# STM32C5A3xx register map
File version: 1.0
Registers are 32-bit, read-write, reset 0x0 unless marked. A register's access mark holds for its fields unless they carry their own. Offsets are from the block's base; [hi:lo] are bit positions; {n}, {i} and the like mark numbered series.

## RCC — Reset and clock control (RCC)
Base 0x44020C00
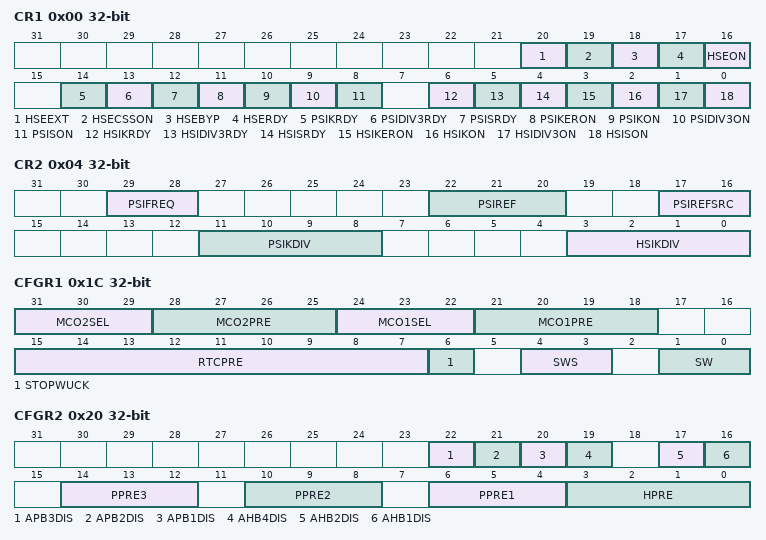
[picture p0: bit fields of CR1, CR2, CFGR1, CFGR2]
0x00 CR1 — RCC clock control register
  [20] HSEEXT
  [19] HSECSSON
  [18] HSEBYP — HSE clock bypass
  [17] HSERDY — HSE clock ready flag
  [16] HSEON — HSE clock enable
  [14] PSIKRDY — PSIK clock ready flag
  [13] PSIDIV3RDY — PSIDIV3 clock ready flag
  [12] PSISRDY — PSIS clock ready flag
  [11] PSIKERON — PSI clock enable in Stop mode
  [10] PSIKON — PSIK clock enable
  [9] PSIDIV3ON — PSIDIV3 clock enable
  [8] PSISON — PSIS clock enable
  [6] HSIKRDY — HSIK clock ready flag
  [5] HSIDIV3RDY — HSIDIV3 clock ready flag
  [4] HSISRDY — HSIS clock ready flag
  [3] HSIKERON — HSI clock enable in Stop mode
  [2] HSIKON — HSIK clock enable
  [1] HSIDIV3ON — HSIDIV3 clock enable
  [0] HSISON — HSIS clock enable
0x04 CR2 — RCC clock control register
  [29:28] PSIFREQ
  [22:20] PSIREF
  [17:16] PSIREFSRC
  [11:8] PSIKDIV — PSI clock out divider factor
  [3:0] HSIKDIV — HSI clock out divider factor
0x1C CFGR1 — RCC clock configuration register1
  [31:29] MCO2SEL — Microcontroller clock output 2
  [28:25] MCO2PRE — MCO2 prescaler
  [24:22] MCO1SEL — Microcontroller clock output 1
  [21:18] MCO1PRE — MCO1 prescaler
  [15:7] RTCPRE
  [6] STOPWUCK
  [4:3] SWS — System clock switch status
  [1:0] SW
0x20 CFGR2 — RCC CPU domain clock configuration register 2
  [22] APB3DIS
  [21] APB2DIS — APB2 clock disable value
  [20] APB1DIS — APB1 clock disable value
  [19] AHB4DIS — AHB4 clock disable value
  [17] AHB2DIS — AHB2 clock disable
  [16] AHB1DIS — AHB1 clock disable
  [14:12] PPRE3 — APB low-speed prescaler (APB3)
  [10:8] PPRE2 — APB high-speed prescaler (APB2)
  [6:4] PPRE1 — APB low-speed prescaler (APB1)
  [3:0] HPRE — AHB prescaler
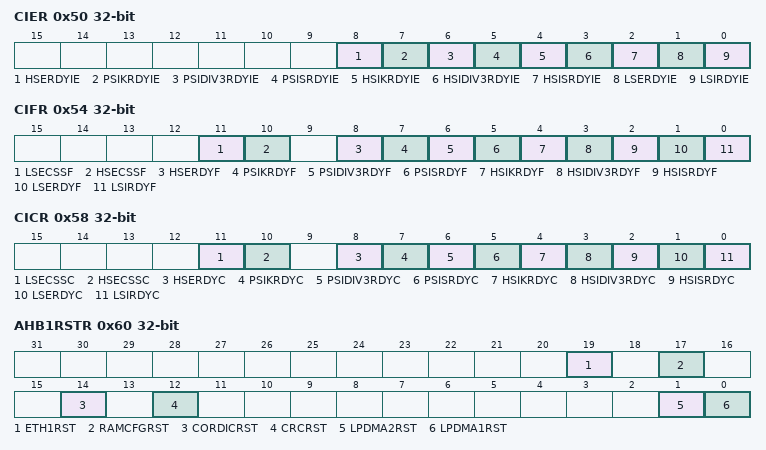
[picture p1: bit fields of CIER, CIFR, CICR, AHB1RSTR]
0x50 CIER — RCC clock source interrupt enable register
  [8] HSERDYIE — HSE ready interrupt enable
  [7] PSIKRDYIE — PSIK ready interrupt enable
  [6] PSIDIV3RDYIE — PSIDIV3 ready interrupt enable
  [5] PSISRDYIE — PSIS ready interrupt enable
  [4] HSIKRDYIE — HSIK ready interrupt enable
  [3] HSIDIV3RDYIE — HSIDIV3 ready interrupt enable
  [2] HSISRDYIE — HSIS ready interrupt enable
  [1] LSERDYIE — LSE ready interrupt enable
  [0] LSIRDYIE — LSI ready interrupt enable
0x54 CIFR ro — RCC clock source interrupt flag register
  [11] LSECSSF
  [10] HSECSSF
  [8] HSERDYF — HSE ready interrupt flag
  [7] PSIKRDYF — PSIK ready interrupt flag
  [6] PSIDIV3RDYF — PSIDIV3 ready interrupt flag
  [5] PSISRDYF — PSIS ready interrupt flag
  [4] HSIKRDYF — HSIK ready interrupt flag
  [3] HSIDIV3RDYF — HSIDIV3 ready interrupt flag
  [2] HSISRDYF — HSIS ready interrupt flag
  [1] LSERDYF — LSE ready interrupt flag
  [0] LSIRDYF — LSI ready interrupt flag
0x58 CICR — RCC clock source interrupt clear register
  [11] LSECSSC
  [10] HSECSSC
  [8] HSERDYC — HSE ready interrupt clear
  [7] PSIKRDYC — PSIK ready interrupt clear
  [6] PSIDIV3RDYC — PSIDIV3 ready interrupt clear
  [5] PSISRDYC — PSIS ready interrupt clear
  [4] HSIKRDYC — HSIK ready interrupt clear
  [3] HSIDIV3RDYC — HSIDIV3 ready interrupt clear
  [2] HSISRDYC — HSIS ready interrupt clear
  [1] LSERDYC — LSE ready interrupt clear
  [0] LSIRDYC — LSI ready interrupt clear
0x60 AHB1RSTR — RCC AHB1 reset register
  [19] ETH1RST — ETH1RST (EHT1 block reset)
  [17] RAMCFGRST — RAMCFG reset
  [14] CORDICRST — CORDIC reset
  [12] CRCRST — CRC reset
  [1] LPDMA2RST — LPDMA2 reset
  [0] LPDMA1RST — LPDMA1 reset
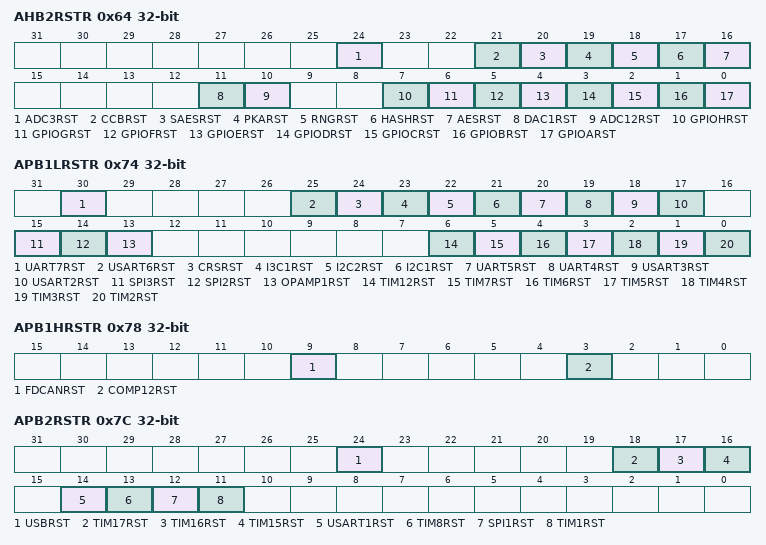
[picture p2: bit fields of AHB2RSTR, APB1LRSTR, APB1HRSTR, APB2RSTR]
0x64 AHB2RSTR — RCC AHB2 peripheral reset register
  [24] ADC3RST — ADC3 reset
  [21] CCBRST — CCBRST (CCB block reset)
  [20] SAESRST — SAESRST (SAES block reset)
  [19] PKARST — PKARST (PKA block reset)
  [18] RNGRST — RNG reset
  [17] HASHRST — HASH reset
  [16] AESRST — AES reset
  [11] DAC1RST — DAC reset
  [10] ADC12RST — ADC1 and ADC2 reset
  [7] GPIOHRST — GPIOH reset
  [6] GPIOGRST — GPIOG reset
  [5] GPIOFRST — GPIOF reset
  [4] GPIOERST — GPIOE reset
  [3] GPIODRST — GPIOD reset
  [2] GPIOCRST — GPIOC reset
  [1] GPIOBRST — GPIOB reset
  [0] GPIOARST — GPIOA reset
0x6C AHB4RSTR — RCC AHB4 peripheral reset register
  [20] XSPI1RST — XSPI1 reset
0x74 APB1LRSTR — RCC APB1 peripheral low reset register
  [30] UART7RST — UART7RST (UART7 block reset)
  [25] USART6RST — USART6RST (USART6 block reset)
  [24] CRSRST — CRS reset
  [23] I3C1RST — I3C1 block reset
  [22] I2C2RST — I2C2 reset
  [21] I2C1RST — I2C1 reset
  [20] UART5RST — UART5 reset
  [19] UART4RST — UART4 reset
  [18] USART3RST — USART3 reset
  [17] USART2RST — USART2 reset
  [15] SPI3RST — SPI3 reset
  [14] SPI2RST — SPI2 reset
  [13] OPAMP1RST — OPAMP1 reset
  [6] TIM12RST — TIM12 reset
  [5] TIM7RST — TIM7 reset
  [4] TIM6RST — TIM6 reset
  [3] TIM5RST — TIM5 reset
  [2] TIM4RST — TIM4RST (TIM4 block reset)
  [1] TIM3RST — TIM3 reset
  [0] TIM2RST — TIM2 reset
0x78 APB1HRSTR — RCC APB1 peripheral high reset register
  [9] FDCANRST — FDCAN1 reset
  [3] COMP12RST — COMP1 and COMP2 reset
0x7C APB2RSTR — RCC APB2 peripheral reset register
  [24] USBRST — USBRST (USB block reset)
  [18] TIM17RST — TIM17 reset
  [17] TIM16RST — TIM16 reset
  [16] TIM15RST — TIM15 reset
  [14] USART1RST — USART1 reset
  [13] TIM8RST — TIM8 reset
  [12] SPI1RST — SPI1 reset
  [11] TIM1RST — TIM1 reset
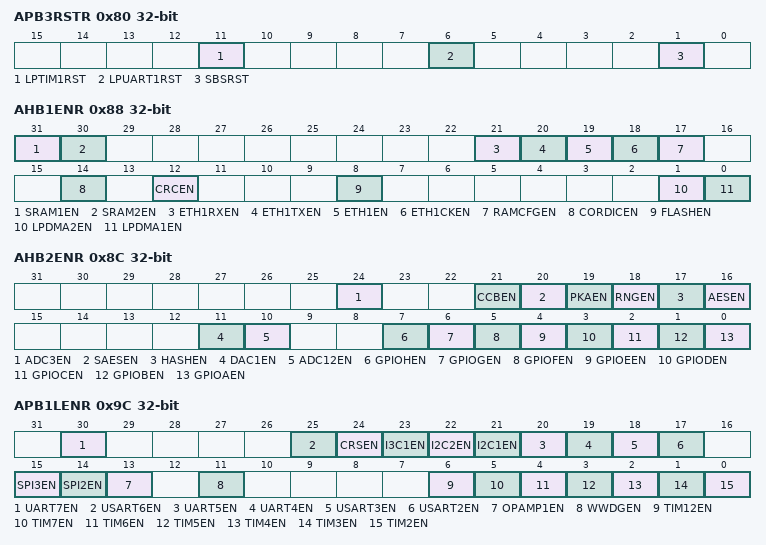
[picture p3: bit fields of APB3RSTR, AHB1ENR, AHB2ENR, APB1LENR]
0x80 APB3RSTR — RCC APB3 peripheral reset register
  [11] LPTIM1RST — LPTIM1RST (LPTIM1 block reset)
  [6] LPUART1RST — LPUART1 reset
  [1] SBSRST — SBS reset
0x88 AHB1ENR — RCC AHB1 peripheral clock register
  [31] SRAM1EN — SRAM1 clock enable
  [30] SRAM2EN — SRAM2 clock enable
  [21] ETH1RXEN — ETH1RXEN (ETH1RX clock enable)
  [20] ETH1TXEN — ETH1TXEN (ETH1TX clock enable)
  [19] ETH1EN — ETH1EN (ETH1 clock enable)
  [18] ETH1CKEN — ETH1CKEN (ETH1CK clock enable)
  [17] RAMCFGEN — RAMCFG clock enable
  [14] CORDICEN — CORDIC clock enable
  [12] CRCEN — CRC clock enable
  [8] FLASHEN — Flash interface clock enable
  [1] LPDMA2EN — LPDMA2 clock enable
  [0] LPDMA1EN — LPDMA1 clock enable
0x8C AHB2ENR — RCC AHB2 peripheral clock register
  [24] ADC3EN — ADC3 clock enable
  [21] CCBEN — CCBEN (CCB clock enable)
  [20] SAESEN — SAESEN (SAES clock enable)
  [19] PKAEN — PKAEN (PKA clock enable)
  [18] RNGEN — RNG clock enable
  [17] HASHEN — HASH clock enable
  [16] AESEN — AES clock enable
  [11] DAC1EN — DAC1 clock enable
  [10] ADC12EN — ADC1 and ADC2 clock enable
  [7] GPIOHEN — GPIOH clock enable
  [6] GPIOGEN — GPIOG clock enable
  [5] GPIOFEN — GPIOF clock enable
  [4] GPIOEEN — GPIOE clock enable
  [3] GPIODEN — GPIOD clock enable
  [2] GPIOCEN — GPIOC clock enable
  [1] GPIOBEN — GPIOB clock enable
  [0] GPIOAEN — GPIOA clock enable
0x94 AHB4ENR — RCC AHB4 peripheral clock register
  [20] XSPI1EN — XSPI1 clock enable
0x9C APB1LENR — RCC APB1 peripheral clock register
  [30] UART7EN — UART7EN (UART7 clock enable)
  [25] USART6EN — USART6EN (USART6 clock enable)
  [24] CRSEN — CRS clock enable
  [23] I3C1EN — I3C1 clock enable
  [22] I2C2EN — I2C2 clock enable
  [21] I2C1EN — I2C1 clock enable
  [20] UART5EN — UART5 clock enable
  [19] UART4EN — UART4 clock enable
  [18] USART3EN — USART3 clock enable
  [17] USART2EN — USART2 clock enable
  [15] SPI3EN — SPI3 clock enable
  [14] SPI2EN — SPI2 clock enable
  [13] OPAMP1EN — OPAMP1 clock enable
  [11] WWDGEN — WWDG clock enable
  [6] TIM12EN — TIM12 clock enable
  [5] TIM7EN — TIM7 clock enable
  [4] TIM6EN — TIM6 clock enable
  [3] TIM5EN — TIM5 clock enable
  [2] TIM4EN — TIM4EN (TIM4 clock enable)
  [1] TIM3EN — TIM3 clock enable
  [0] TIM2EN — TIM2 clock enable
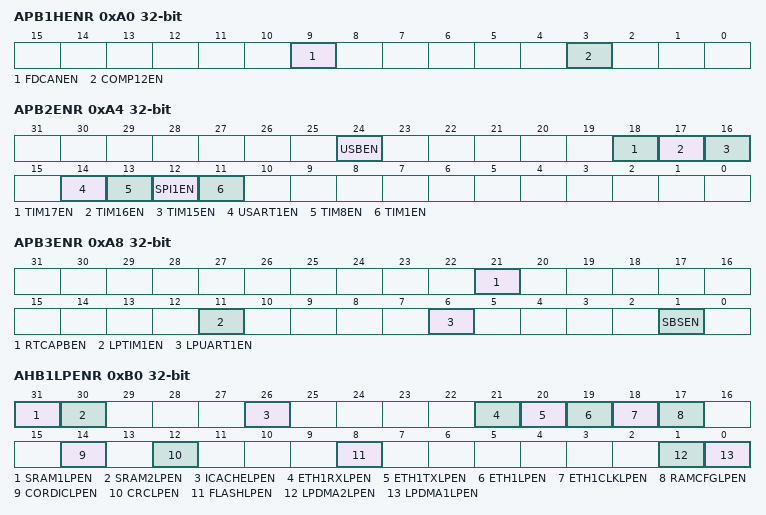
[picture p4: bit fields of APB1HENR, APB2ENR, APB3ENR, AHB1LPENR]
0xA0 APB1HENR — RCC APB1 peripheral clock register
  [9] FDCANEN — FDCAN1 clock enable
  [3] COMP12EN — COMP1 and COMP2 clock enable
0xA4 APB2ENR — RCC APB2 peripheral clock register
  [24] USBEN — USBEN (USB clock enable)
  [18] TIM17EN — TIM17 clock enable
  [17] TIM16EN — TIM16 clock enable
  [16] TIM15EN — TIM15 clock enable
  [14] USART1EN — USART1 clock enable
  [13] TIM8EN — TIM8 clock enable
  [12] SPI1EN — SPI1 clock enable
  [11] TIM1EN — TIM1 clock enable
0xA8 APB3ENR — RCC APB3 peripheral clock register
  [21] RTCAPBEN — RTC APB interface clock enable
  [11] LPTIM1EN — LPTIM1EN (LPTIM1 clock enable)
  [6] LPUART1EN — LPUART1 clock enable
  [1] SBSEN — SBS clock enable
0xB0 AHB1LPENR — RCC AHB1 sleep clock register
  [31] SRAM1LPEN, [30] SRAM2LPEN, [26] ICACHELPEN, [21] ETH1RXLPEN, [20] ETH1TXLPEN, [19] ETH1LPEN, [18] ETH1CLKLPEN, [17] RAMCFGLPEN, [14] CORDICLPEN, [12] CRCLPEN, [8] FLASHLPEN, [1] LPDMA2LPEN, [0] LPDMA1LPEN
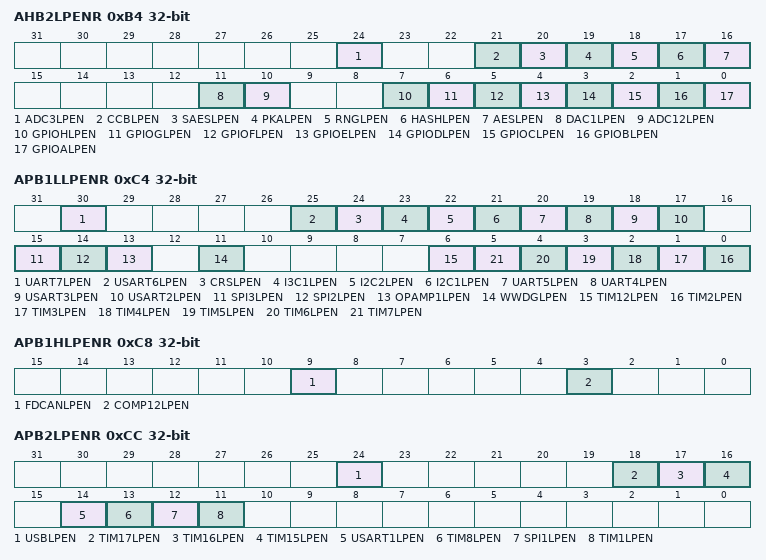
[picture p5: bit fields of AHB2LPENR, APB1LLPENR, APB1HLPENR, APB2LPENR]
0xB4 AHB2LPENR — RCC AHB2 sleep clock register
  [24] ADC3LPEN, [21] CCBLPEN, [20] SAESLPEN, [19] PKALPEN, [18] RNGLPEN, [17] HASHLPEN, [16] AESLPEN, [11] DAC1LPEN, [10] ADC12LPEN, [7] GPIOHLPEN, [6] GPIOGLPEN, [5] GPIOFLPEN, [4] GPIOELPEN, [3] GPIODLPEN, [2] GPIOCLPEN, [1] GPIOBLPEN, [0] GPIOALPEN
0xBC AHB4LPENR — RCC AHB4 peripheral sleep clock register
  [20] XSPI1LPEN
0xC4 APB1LLPENR — RCC APB1 sleep clock register
  [30] UART7LPEN, [25] USART6LPEN, [24] CRSLPEN, [23] I3C1LPEN, [22] I2C2LPEN, [21] I2C1LPEN, [20] UART5LPEN, [19] UART4LPEN, [18] USART3LPEN, [17] USART2LPEN, [15] SPI3LPEN, [14] SPI2LPEN, [13] OPAMP1LPEN, [11] WWDGLPEN, [6] TIM12LPEN, [n-2] TIM{n}LPEN (n=2..7)
0xC8 APB1HLPENR — RCC APB1 sleep clock register
  [9] FDCANLPEN, [3] COMP12LPEN
0xCC APB2LPENR — RCC APB2 sleep clock register
  [24] USBLPEN, [18] TIM17LPEN, [17] TIM16LPEN, [16] TIM15LPEN, [14] USART1LPEN, [13] TIM8LPEN, [12] SPI1LPEN, [11] TIM1LPEN
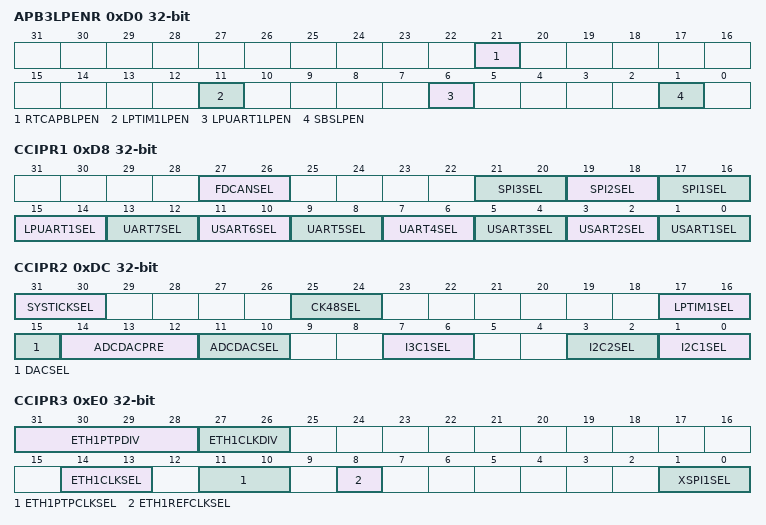
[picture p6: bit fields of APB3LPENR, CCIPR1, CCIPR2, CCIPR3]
0xD0 APB3LPENR — RCC APB3 sleep clock register
  [21] RTCAPBLPEN, [11] LPTIM1LPEN, [6] LPUART1LPEN, [1] SBSLPEN
0xD8 CCIPR1 — RCC kernel clock configuration register
  [27:26] FDCANSEL, [21:20] SPI3SEL, [19:18] SPI2SEL, [17:16] SPI1SEL, [15:14] LPUART1SEL, [13:12] UART7SEL, [11:10] USART6SEL, [9:8] UART5SEL, [7:6] UART4SEL, [5:4] USART3SEL, [3:2] USART2SEL, [1:0] USART1SEL
0xDC CCIPR2 — RCC kernel clock configuration register
  [31:30] SYSTICKSEL — SYSTICK clock source selection
  [25:24] CK48SEL — CK48 clock source selection
  [17:16] LPTIM1SEL
  [15] DACSEL — DAC sample and hold clock
  [14:12] ADCDACPRE
  [11:10] ADCDACSEL
  [7:6] I3C1SEL
  [3:2] I2C2SEL
  [1:0] I2C1SEL
0xE0 CCIPR3 — RCC kernel clock configuration register
  [31:28] ETH1PTPDIV — Ethernet PTP clock division
  [27:26] ETH1CLKDIV — Ethernet clock division
  [14:13] ETH1CLKSEL
  [11:10] ETH1PTPCLKSEL
  [8] ETH1REFCLKSEL
  [1:0] XSPI1SEL
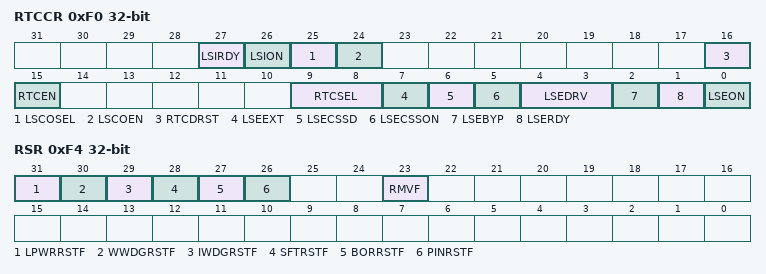
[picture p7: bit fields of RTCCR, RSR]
0xF0 RTCCR — RCC RTC domain control register
  [27] LSIRDY — LSI oscillator ready
  [26] LSION — LSI oscillator enable
  [25] LSCOSEL
  [24] LSCOEN
  [16] RTCDRST — RTC domain software reset
  [15] RTCEN — RTC clock enable
  [9:8] RTCSEL — RTC clock source selection
  [7] LSEEXT
  [6] LSECSSD
  [5] LSECSSON
  [4:3] LSEDRV
  [2] LSEBYP — LSE oscillator bypass
  [1] LSERDY — LSE oscillator ready
  [0] LSEON — LSE oscillator enabled
0xF4 RSR — RCC reset status register
  [31] LPWRRSTF — Low-power reset flag
  [30] WWDGRSTF — Window watchdog reset flag
  [29] IWDGRSTF — Independent watchdog reset flag
  [28] SFTRSTF
  [27] BORRSTF — POR reset flag
  [26] PINRSTF — Pin reset flag (NRST)
  [23] RMVF — Remove reset flag
0x114 PRIVCFGR — RCC privilege configuration register
  [1] PRIV
